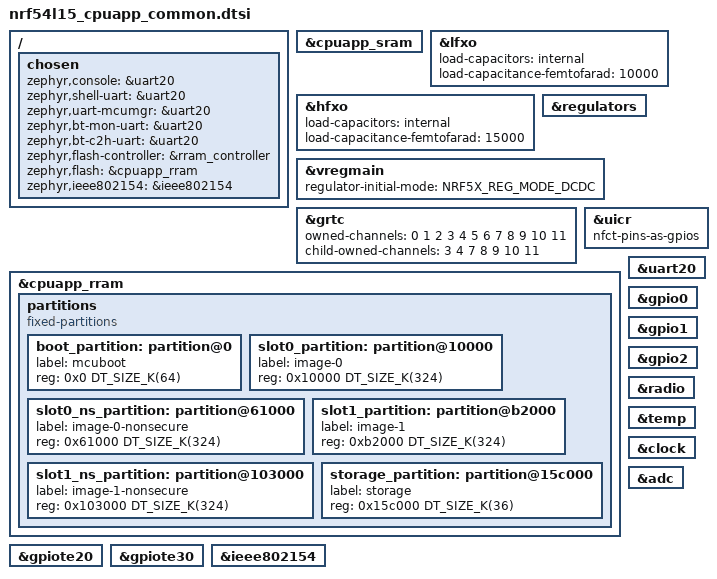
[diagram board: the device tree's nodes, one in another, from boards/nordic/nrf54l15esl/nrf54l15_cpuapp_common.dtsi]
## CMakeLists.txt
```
# SPDX-License-Identifier: Apache-2.0

cmake_minimum_required(VERSION 3.20.0)

find_package(Zephyr REQUIRED HINTS $ENV{ZEPHYR_BASE})
project(pawr_mosaic)

target_sources(app PRIVATE 
	src/main.c
	src/pawr.c
)
```

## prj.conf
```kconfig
CONFIG_HEAP_MEM_POOL_SIZE=16384

CONFIG_LOG=y
CONFIG_CONSOLE=y
CONFIG_SHELL=y
CONFIG_SERIAL=y
CONFIG_UART_CONSOLE_LOG_LEVEL_DBG=y
CONFIG_UART_LOG_LEVEL_DBG=y

CONFIG_SPI=y
  
CONFIG_UART_NRFX_UARTE_LEGACY_SHIM=y

CONFIG_LV_Z_MEM_POOL_SIZE=16384
CONFIG_LV_Z_SHELL=y

CONFIG_PM_DEVICE=y
CONFIG_PM_DEVICE_RUNTIME=y

CONFIG_LV_Z_MEM_POOL_SIZE=16384
CONFIG_LV_Z_SHELL=y
CONFIG_MAIN_STACK_SIZE=4096

CONFIG_DISPLAY=y
CONFIG_DISPLAY_LOG_LEVEL_INF=y

CONFIG_SENSOR=y
CONFIG_SENSOR_SHELL=y

CONFIG_INPUT=y
CONFIG_INPUT_SHELL=y
CONFIG_INPUT_LOG_LEVEL_DBG=y

CONFIG_LVGL=y
CONFIG_LV_Z_FLUSH_THREAD=y
CONFIG_LV_MEM_CUSTOM=y
CONFIG_LV_USE_LOG=y
CONFIG_LV_USE_LABEL=y
CONFIG_LV_USE_BTN=y
CONFIG_LV_USE_ARC=y
CONFIG_LV_USE_IMG=y
CONFIG_LV_USE_MONKEY=y
CONFIG_LV_FONT_MONTSERRAT_14=y

CONFIG_LV_COLOR_DEPTH_1=y
CONFIG_LV_Z_VDB_SIZE=16
CONFIG_LV_DPI_DEF=130
CONFIG_LV_Z_BITS_PER_PIXEL=1

CONFIG_LV_LOG_LEVEL_INFO=y

CONFIG_BT=y
CONFIG_BT_OBSERVER=y
CONFIG_BT_BROADCASTER=y
CONFIG_BT_EXT_ADV=y
CONFIG_BT_PER_ADV_SYNC=y
CONFIG_BT_DEVICE_NAME="PAwR sync sample"

CONFIG_BT_MAX_CONN=1
CONFIG_BT_PERIPHERAL=y
CONFIG_BT_PER_ADV_SYNC_TRANSFER_SENDER=y
CONFIG_BT_PER_ADV_SYNC_TRANSFER_RECEIVER=y

CONFIG_BT_PER_ADV_SYNC_RSP=y
CONFIG_BT_PER_ADV_SYNC_BUF_SIZE=247
```

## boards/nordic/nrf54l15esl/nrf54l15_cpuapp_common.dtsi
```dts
/*
 * Copyright (c) 2024 Nordic Semiconductor ASA
 *
 * SPDX-License-Identifier: Apache-2.0
 */

/* This file is common to the secure and non-secure domain */

#include <nordic/nrf54l15_cpuapp.dtsi>
#include "nrf54l15esl_nrf54l15-common.dtsi"

/ {
	chosen {
		zephyr,console = &uart20;
		zephyr,shell-uart = &uart20;
		zephyr,uart-mcumgr = &uart20;
		zephyr,bt-mon-uart = &uart20;
		zephyr,bt-c2h-uart = &uart20;
		zephyr,flash-controller = &rram_controller;
		zephyr,flash = &cpuapp_rram;
		zephyr,ieee802154 = &ieee802154;
	};
};

&cpuapp_sram {
	status = "okay";
};

&lfxo {
	load-capacitors = "internal";
	load-capacitance-femtofarad = <10000>;
};

&hfxo {
	load-capacitors = "internal";
	load-capacitance-femtofarad = <15000>;
};

&regulators {
	status = "okay";
};

&vregmain {
	status = "okay";
	regulator-initial-mode = <NRF5X_REG_MODE_DCDC>;
};

&grtc {
	owned-channels = <0 1 2 3 4 5 6 7 8 9 10 11>;
	/* Channels 7-11 reserved for Zero Latency IRQs, 3-4 for FLPR */
	child-owned-channels = <3 4 7 8 9 10 11>;
	status = "okay";
};

&uicr {
	nfct-pins-as-gpios;
};

&cpuapp_rram {
	partitions {
		compatible = "fixed-partitions";
		#address-cells = <1>;
		#size-cells = <1>;
		boot_partition: partition@0 {
			label = "mcuboot";
			reg = <0x0 DT_SIZE_K(64)>;
		};
		slot0_partition: partition@10000 {
			label = "image-0";
			reg = <0x10000 DT_SIZE_K(324)>;
		};
		slot0_ns_partition: partition@61000 {
			label = "image-0-nonsecure";
			reg = <0x61000 DT_SIZE_K(324)>;
		};
		slot1_partition: partition@b2000 {
			label = "image-1";
			reg = <0xb2000 DT_SIZE_K(324)>;
		};
		slot1_ns_partition: partition@103000 {
			label = "image-1-nonsecure";
			reg = <0x103000 DT_SIZE_K(324)>;
		};
		/* 32k from 0x154000 to 0x15bfff reserved for TF-M partitions */
		storage_partition: partition@15c000 {
			label = "storage";
			reg = <0x15c000 DT_SIZE_K(36)>;
		};
	};
};

&uart20 {
	status = "okay";
};

&gpio0 {
	status = "okay";
};

&gpio1 {
	status = "okay";
};

&gpio2 {
	status = "okay";
};

&gpiote20 {
	status = "okay";
};

&gpiote30 {
	status = "okay";
};

&radio {
	status = "okay";
};

&ieee802154 {
	status = "okay";
};

&temp {
	status = "okay";
};

&clock {
	status = "okay";
};

&adc {
	status = "okay";
};
```

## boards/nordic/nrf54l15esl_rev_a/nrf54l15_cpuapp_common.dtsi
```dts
/*
 * Copyright (c) 2024 Nordic Semiconductor ASA
 *
 * SPDX-License-Identifier: Apache-2.0
 */

/* This file is common to the secure and non-secure domain */

#include <nordic/nrf54l15_cpuapp.dtsi>
#include "nrf54l15esl_rev_a_nrf54l15-common.dtsi"

/ {
	chosen {
		zephyr,console = &uart20;
		zephyr,shell-uart = &uart20;
		zephyr,uart-mcumgr = &uart20;
		zephyr,bt-mon-uart = &uart20;
		zephyr,bt-c2h-uart = &uart20;
		zephyr,flash-controller = &rram_controller;
		zephyr,flash = &cpuapp_rram;
		zephyr,ieee802154 = &ieee802154;
	};
};

&cpuapp_sram {
	status = "okay"; };

&lfxo {
	load-capacitors = "internal";
	load-capacitance-femtofarad = <10000>;
};

&hfxo {
	load-capacitors = "internal";
	load-capacitance-femtofarad = <15000>;
};

/*
&regulators {
	status = "okay";
};

&vregmain {
	status = "disabled";
	//regulator-initial-mode = <NRF5X_REG_MODE_DCDC>;
};
*/

&grtc {
	owned-channels = <0 1 2 3 4 5 6 7 8 9 10 11>;
	/* Channels 7-11 reserved for Zero Latency IRQs, 3-4 for FLPR */
	child-owned-channels = <3 4 7 8 9 10 11>;
	status = "okay";
};

&uicr {
	nfct-pins-as-gpios;
};

&cpuapp_rram {
	partitions {
		compatible = "fixed-partitions";
		#address-cells = <1>;
		#size-cells = <1>;
		boot_partition: partition@0 {
			label = "mcuboot";
			reg = <0x0 DT_SIZE_K(64)>;
		};
		slot0_partition: partition@10000 {
			label = "image-0";
			reg = <0x10000 DT_SIZE_K(324)>;
		};
		slot0_ns_partition: partition@61000 {
			label = "image-0-nonsecure";
			reg = <0x61000 DT_SIZE_K(324)>;
		};
		slot1_partition: partition@b2000 {
			label = "image-1";
			reg = <0xb2000 DT_SIZE_K(324)>;
		};
		slot1_ns_partition: partition@103000 {
			label = "image-1-nonsecure";
			reg = <0x103000 DT_SIZE_K(324)>;
		};
		/* 32k from 0x154000 to 0x15bfff reserved for TF-M partitions */
		storage_partition: partition@15c000 {
			label = "storage";
			reg = <0x15c000 DT_SIZE_K(36)>;
		};
	};
};

&uart20 {
	status = "okay";
};

&gpio0 {
	status = "okay";
};

&gpio1 {
	status = "okay";
};

&gpio2 {
	status = "okay";
};

&gpiote20 {
	status = "okay";
};

&gpiote30 {
	status = "okay";
};

&radio {
	status = "okay";
};

&ieee802154 {
	status = "okay";
};

&temp {
	status = "okay";
};

&clock {
	status = "okay";
};

&adc {
	status = "okay";
};
```

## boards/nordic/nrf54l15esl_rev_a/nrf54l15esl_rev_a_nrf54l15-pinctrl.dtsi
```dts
/*
 * Copyright (c) 2024 Nordic Semiconductor
 * SPDX-License-Identifier: Apache-2.0
 */

&pinctrl {
	/omit-if-no-ref/ uart20_default: uart20_default {
		group1 {
			psels = <NRF_PSEL(UART_TX, 1, 4)>;
		};
		group2 {
			psels = <NRF_PSEL(UART_RX, 1, 2)>;
			bias-pull-up;
		};
	};

	/omit-if-no-ref/ uart20_sleep: uart20_sleep {
		group1 {
			psels = <NRF_PSEL(UART_TX, 1, 4)>,
				<NRF_PSEL(UART_RX, 1, 2)>;
			low-power-enable;
		};
	};

	/omit-if-no-ref/ spi21_default: spi21_default {
		group1 {
			psels = <NRF_PSEL(SPIM_SCK, 1, 11)>,
				<NRF_PSEL(SPIM_MOSI, 1, 10)>;
		};
	};

	/omit-if-no-ref/ spi21_sleep: spi21_sleep {
		group1 {
			psels = <NRF_PSEL(SPIM_SCK, 1, 11)>,
				<NRF_PSEL(SPIM_MOSI, 1, 10)>;
		};
		low-power-enable;
	};

	/omit-if-no-ref/ i2c30_default: i2c30_default {
		group1 {
			psels = <NRF_PSEL(TWIM_SDA, 0, 3)>,
				<NRF_PSEL(TWIM_SCL, 0, 4)>;
		};
	};

	/omit-if-no-ref/ i2c30_sleep: i2c30_sleep {
		group1 {
			psels = <NRF_PSEL(TWIM_SDA, 0, 3)>,
				<NRF_PSEL(TWIM_SCL, 0, 4)>;
		};
		low-power-enable;
	};
};
```

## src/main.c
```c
/*
 * Copyright (c) 2018 Jan Van Winkel <jan.van_winkel@dxplore.eu>
 *
 * SPDX-License-Identifier: Apache-2.0
 */

#include <zephyr/device.h>
#include <zephyr/pm/device.h>
#include <zephyr/devicetree.h>
#include <zephyr/drivers/display.h>
#include <zephyr/drivers/gpio.h>
#include <lvgl.h>
#include <stdio.h>
#include <string.h>
#include <zephyr/kernel.h>
#include <lvgl_input_device.h>

#define LOG_LEVEL CONFIG_LOG_DEFAULT_LEVEL
#include <zephyr/logging/log.h>
LOG_MODULE_REGISTER(app);

const struct device *display_spi = DEVICE_DT_GET(DT_PROP(DT_PARENT(DT_CHOSEN(zephyr_display)), spi_dev));

int main(void) {
	const struct device *display_dev;

	display_dev = DEVICE_DT_GET(DT_CHOSEN(zephyr_display));
	if (!device_is_ready(display_dev)) {
		LOG_ERR("Device not ready, aborting test");
	}

	uint8_t my_str[] = "Hey!";
	uint8_t other_str[] = "What's good?";
	lv_obj_t *label = lv_label_create(lv_scr_act());
	lv_label_set_text(label, my_str);
	lv_obj_align(label, LV_ALIGN_CENTER, 0, 0);
	lv_task_handler();

	int ret;
	while (true) {
		LOG_INF("Suspending display");
		ret = pm_device_action_run(display_dev, PM_DEVICE_ACTION_SUSPEND);
		if (ret < 0) {
			LOG_ERR("Could not suspend the display (err %d)", ret);
		}

		LOG_INF("Suspending display bus");
		ret = pm_device_action_run(display_spi, PM_DEVICE_ACTION_SUSPEND);
		if (ret < 0) {
			LOG_ERR("Could not suspend the display bus (err %d)", ret);
			return ret;
		}
		k_msleep(5000);
		LOG_INF("Resuming display bus");
		ret = pm_device_action_run(display_spi, PM_DEVICE_ACTION_RESUME);
		if (ret < 0) {
			LOG_ERR("Could not resume the display (err %d)", ret);
			return ret;
		}
		LOG_INF("Resuming display");
		ret = pm_device_action_run(display_dev, PM_DEVICE_ACTION_RESUME);
		if (ret < 0) {
			LOG_ERR("Could not resume the display (err %d)", ret);
		}
		lv_label_set_text(label, other_str);
		k_msleep(100);
		lv_task_handler();
		k_msleep(1000);
		lv_label_set_text(label, my_str);
		k_msleep(100);
		lv_task_handler();
	}
}
```

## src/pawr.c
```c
#include <zephyr/bluetooth/bluetooth.h>
#include <zephyr/bluetooth/conn.h>
#include <zephyr/bluetooth/gatt.h>
#include <zephyr/bluetooth/uuid.h>
#include <zephyr/bluetooth/hci.h>
#include <zephyr/sys/util.h>

#define NAME_LEN 30

static K_SEM_DEFINE(sem_per_adv, 0, 1);
static K_SEM_DEFINE(sem_per_sync, 0, 1);
static K_SEM_DEFINE(sem_per_sync_lost, 0, 1);

static struct bt_conn *default_conn;
static struct bt_le_per_adv_sync *default_sync;
static struct __packed {
	uint8_t subevent;
	uint8_t response_slot;

} pawr_timing;

static void sync_cb(struct bt_le_per_adv_sync *sync, struct bt_le_per_adv_sync_synced_info *info)
{
	struct bt_le_per_adv_sync_subevent_params params;
	uint8_t subevents[1];
	char le_addr[BT_ADDR_LE_STR_LEN];
	int err;

	bt_addr_le_to_str(info->addr, le_addr, sizeof(le_addr));
	printk("Synced to %s with %d subevents\n", le_addr, info->num_subevents);

	default_sync = sync;

	params.properties = 0;
	params.num_subevents = 1;
	params.subevents = subevents;
	subevents[0] = pawr_timing.subevent;

	err = bt_le_per_adv_sync_subevent(sync, &params);
	if (err) {
		printk("Failed to set subevents to sync to (err %d)\n", err);
	} else {
		printk("Changed sync to subevent %d\n", subevents[0]);
	}

	k_sem_give(&sem_per_sync);
}

static void term_cb(struct bt_le_per_adv_sync *sync,
		    const struct bt_le_per_adv_sync_term_info *info)
{
	char le_addr[BT_ADDR_LE_STR_LEN];

	bt_addr_le_to_str(info->addr, le_addr, sizeof(le_addr));

	printk("Sync terminated (reason %d)\n", info->reason);

	default_sync = NULL;

	k_sem_give(&sem_per_sync_lost);
}

static bool print_ad_field(struct bt_data *data, void *user_data)
{
	ARG_UNUSED(user_data);

	printk("    0x%02X: ", data->type);
	for (size_t i = 0; i < data->data_len; i++) {
		printk("%02X", data->data[i]);
	}

	printk("\n");

	return true;
}

int bt_le_per_adv_set_response_data(struct bt_le_per_adv_sync *per_adv_sync,
				    const struct bt_le_per_adv_response_params *params,
				    const struct net_buf_simple *data);

static struct bt_le_per_adv_response_params rsp_params;

NET_BUF_SIMPLE_DEFINE_STATIC(rsp_buf, 247);

static void recv_cb(struct bt_le_per_adv_sync *sync,
		    const struct bt_le_per_adv_sync_recv_info *info, struct net_buf_simple *buf)
{
	int err;

	if (buf && buf->len) {
		/* Echo the data back to the advertiser */
		net_buf_simple_reset(&rsp_buf);
		net_buf_simple_add_mem(&rsp_buf, buf->data, buf->len);

		rsp_params.request_event = info->periodic_event_counter;
		rsp_params.request_subevent = info->subevent;
		/* Respond in current subevent and assigned response slot */
		rsp_params.response_subevent = info->subevent;
		rsp_params.response_slot = pawr_timing.response_slot;

		printk("Indication: subevent %d, responding in slot %d\n", info->subevent,
		       pawr_timing.response_slot);
		bt_data_parse(buf, print_ad_field, NULL);

		err = bt_le_per_adv_set_response_data(sync, &rsp_params, &rsp_buf);
		if (err) {
			printk("Failed to send response (err %d)\n", err);
		}
	} else if (buf) {
		printk("Received empty indication: subevent %d\n", info->subevent);
	} else {
		printk("Failed to receive indication: subevent %d\n", info->subevent);
	}
}

static struct bt_le_per_adv_sync_cb sync_callbacks = {
	.synced = sync_cb,
	.term = term_cb,
	.recv = recv_cb,
};

static const struct bt_uuid_128 pawr_svc_uuid =
	BT_UUID_INIT_128(BT_UUID_128_ENCODE(0x12345678, 0x1234, 0x5678, 0x1234, 0x56789abcdef0));
static const struct bt_uuid_128 pawr_char_uuid =
	BT_UUID_INIT_128(BT_UUID_128_ENCODE(0x12345678, 0x1234, 0x5678, 0x1234, 0x56789abcdef1));

static ssize_t write_timing(struct bt_conn *conn, const struct bt_gatt_attr *attr, const void *buf,
			    uint16_t len, uint16_t offset, uint8_t flags)
{
	if (offset) {
		return BT_GATT_ERR(BT_ATT_ERR_INVALID_OFFSET);
	}

	if (len != sizeof(pawr_timing)) {
		return BT_GATT_ERR(BT_ATT_ERR_INVALID_ATTRIBUTE_LEN);
	}

	memcpy(&pawr_timing, buf, len);

	printk("New timing: subevent %d, response slot %d\n", pawr_timing.subevent,
	       pawr_timing.response_slot);

	struct bt_le_per_adv_sync_subevent_params params;
	uint8_t subevents[1];
	int err;

	params.properties = 0;
	params.num_subevents = 1;
	params.subevents = subevents;
	subevents[0] = pawr_timing.subevent;

	if (default_sync) {
		err = bt_le_per_adv_sync_subevent(default_sync, &params);
		if (err) {
			printk("Failed to set subevents to sync to (err %d)\n", err);
		} else {
			printk("Changed sync to subevent %d\n", subevents[0]);
		}
	} else {
		printk("Not synced yet\n");
	}

	return len;
}

BT_GATT_SERVICE_DEFINE(pawr_svc, BT_GATT_PRIMARY_SERVICE(&pawr_svc_uuid.uuid),
		       BT_GATT_CHARACTERISTIC(&pawr_char_uuid.uuid, BT_GATT_CHRC_WRITE,
					      BT_GATT_PERM_WRITE, NULL, write_timing,
					      &pawr_timing));

void connected(struct bt_conn *conn, uint8_t err)
{
	printk("Connected, err 0x%02X %s\n", err, bt_hci_err_to_str(err));

	if (err) {
		default_conn = NULL;

		return;
	}

	default_conn = bt_conn_ref(conn);
}

void disconnected(struct bt_conn *conn, uint8_t reason)
{
	bt_conn_unref(default_conn);
	default_conn = NULL;

	printk("Disconnected, reason 0x%02X %s\n", reason, bt_hci_err_to_str(reason));
}

BT_CONN_CB_DEFINE(conn_cb) = {
	.connected = connected,
	.disconnected = disconnected,
};

static const struct bt_data ad[] = {
	BT_DATA(BT_DATA_NAME_COMPLETE, CONFIG_BT_DEVICE_NAME, sizeof(CONFIG_BT_DEVICE_NAME) - 1),
};

int sync_init(void)
{
	struct bt_le_per_adv_sync_transfer_param past_param;
	int err;

	printk("Starting Periodic Advertising with Responses Synchronization Demo\n");

	err = bt_enable(NULL);
	if (err) {
		printk("Bluetooth init failed (err %d)\n", err);

		return 0;
	}

	bt_le_per_adv_sync_cb_register(&sync_callbacks);

	past_param.skip = 1;
	past_param.timeout = 1000; /* 10 seconds */
	past_param.options = BT_LE_PER_ADV_SYNC_TRANSFER_OPT_NONE;
	err = bt_le_per_adv_sync_transfer_subscribe(NULL, &past_param);
	if (err) {
		printk("PAST subscribe failed (err %d)\n", err);

		return 0;
	}

	do {
		err = bt_le_adv_start(
			BT_LE_ADV_PARAM(BT_LE_ADV_OPT_ONE_TIME | BT_LE_ADV_OPT_CONNECTABLE,
					BT_GAP_ADV_FAST_INT_MIN_2, BT_GAP_ADV_FAST_INT_MAX_2, NULL),
			ad, ARRAY_SIZE(ad), NULL, 0);
		if (err && err != -EALREADY) {
			printk("Advertising failed to start (err %d)\n", err);

			return 0;
		}

		printk("Waiting for periodic sync...\n");
		err = k_sem_take(&sem_per_sync, K_SECONDS(10));
		if (err) {
			printk("Timed out while synchronizing\n");

			continue;
		}

		printk("Periodic sync established.\n");

		err = k_sem_take(&sem_per_sync_lost, K_FOREVER);
		if (err) {
			printk("failed (err %d)\n", err);

			return 0;
		}

		printk("Periodic sync lost.\n");
	} while (true);

	return 0;
}

K_THREAD_DEFINE(sync_thread, 1024, sync_init, NULL, NULL, NULL, 7, 0, 0);
```
